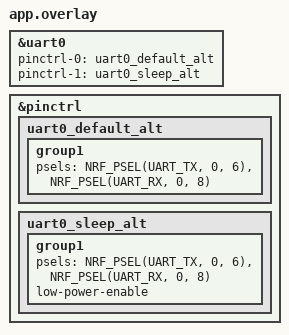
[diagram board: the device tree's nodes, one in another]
&uart0 {
    status = "okay";
    pinctrl-0 = <&uart0_default_alt>;
    pinctrl-1 = <&uart0_sleep_alt>;
    pinctrl-names = "default", "sleep";
};

&pinctrl {
    uart0_default_alt: uart0_default_alt {
        group1 {
            psels = <NRF_PSEL(UART_TX, 0, 6)>,
                    <NRF_PSEL(UART_RX, 0, 8)>;
        };
    };

    uart0_sleep_alt: uart0_sleep_alt {
        group1 {
            psels = <NRF_PSEL(UART_TX, 0, 6)>,
                    <NRF_PSEL(UART_RX, 0, 8)>;
            low-power-enable;
        };
    };
};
